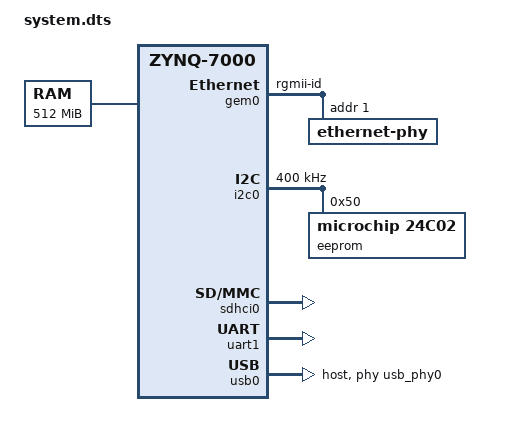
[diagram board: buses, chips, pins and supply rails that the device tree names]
/*
 * CAUTION: This file is automatically generated by Xilinx.
 * Version: HSI 2016.4
 * Today is: Wed Dec 21 16:54:52 2016
*/


/dts-v1/;
/include/ "zynq-7000.dtsi"
/ {
	cpus {
		cpu@0 {
			operating-points = <650000 1000000 325000 1000000>;
		};
	};
	chosen {
		bootargs = "console=ttyPS0,115200 root=/dev/mmcblk0p2 ro rootfstype=ext4 earlyprintk rootwait";
	};
	aliases {
		ethernet0 = &gem0;
		serial0 = &uart1;
	};
	memory {
		device_type = "memory";
		reg = <0x0 0x20000000>;
	};
};
&gem0 {
	local-mac-address = [00 0a 35 00 00 00];
	phy-mode = "rgmii-id";
	status = "okay";
	xlnx,ptp-enet-clock = <0x6750918>;
};
&i2c0 {
	clock-frequency = <400000>;
	status = "okay";
};
&intc {
	num_cpus = <2>;
	num_interrupts = <96>;
};
&sdhci0 {
	status = "okay";
	xlnx,has-cd = <0x0>;
	xlnx,has-power = <0x0>;
	xlnx,has-wp = <0x0>;
};
&uart1 {
	device_type = "serial";
	port-number = <0>;
	status = "okay";
};
&usb0 {
	dr_mode = "host";
	phy_type = "ulpi";
	status = "okay";
};
&clkc {
	fclk-enable = <0x0>;
	ps-clk-frequency = <50000000>;
};

&gem0 {
    ethernet-phy@1 {
        reg = <1>;
    };
};
&i2c0 {
    eeprom@50 {
        /* Microchip 24AA02E48 */
        compatible = "microchip,24c02";
        reg = <0x50>;
        pagesize = <8>;
    };
};
/ {
    usb_phy0: phy0 {
        compatible = "ulpi-phy";
        #phy-cells = <0>;
        reg = <0xe0002000 0x1000>;
        view-port = <0x0170>;
        drv-vbus;
    };
};
&usb0 {
    usb-phy = <&usb_phy0>;
};
